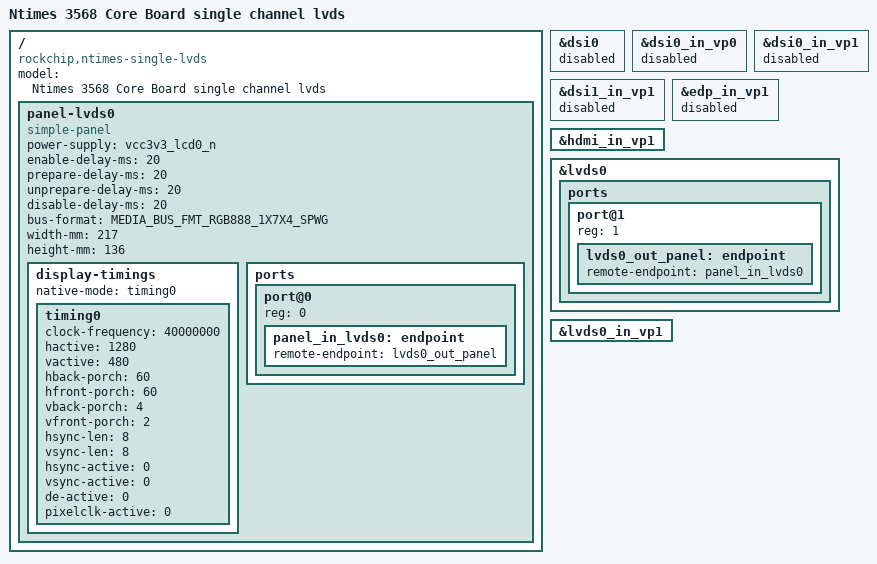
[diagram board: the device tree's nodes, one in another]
// SPDX-License-Identifier: (GPL-2.0+ OR MIT)
/*
 * Copyright (c) 2023 Rockchip Electronics Co., Ltd.
 */

#include <dt-bindings/display/media-bus-format.h>

/ {
	model = "Ntimes 3568 Core Board single channel lvds";
	compatible = "rockchip,ntimes-single-lvds", "rockchip,rk3568";

	/* panel: claa070wp03xg */
	panel-lvds0 {
		compatible = "simple-panel";
		//backlight = <&backlight>;
		power-supply = <&vcc3v3_lcd0_n>;
		enable-delay-ms = <20>;
		prepare-delay-ms = <20>;
		unprepare-delay-ms = <20>;
		disable-delay-ms = <20>;
		bus-format = <MEDIA_BUS_FMT_RGB888_1X7X4_SPWG>;
		width-mm = <217>;
		height-mm = <136>;

		display-timings {
			native-mode = <&timing0>;
			timing0: timing0 {
				clock-frequency = <40000000>;
				hactive = <1280>;
				vactive = <480>;
				hback-porch = <60>;
				hfront-porch = <60>;
				vback-porch = <4>;
				vfront-porch = <2>;
				hsync-len = <8>;
				vsync-len = <8>;
				hsync-active = <0>;
				vsync-active = <0>;
				de-active = <0>;
				pixelclk-active = <0>;
			};
		};

		ports {
			#address-cells = <1>;
			#size-cells = <0>;
			port@0 {
				reg = <0>;
				panel_in_lvds0: endpoint {
					remote-endpoint = <&lvds0_out_panel>;
				};
			};
		};
	};
};

&dsi0 {
	status = "disabled";
};

&dsi0_in_vp0 {
	status = "disabled";
};

&dsi0_in_vp1 {
	status = "disabled";
};

&dsi1_in_vp1 {
	status = "disabled";
};

&edp_in_vp1 {
	status = "disabled";
};

&hdmi_in_vp1 {
	status = "okay";
};

&lvds0 {
	status = "okay";
	ports {
		port@1 {
			reg = <1>;
			lvds0_out_panel: endpoint {
				remote-endpoint = <&panel_in_lvds0>;
			};
		};
	};
};

&lvds0_in_vp1 {
	status = "okay";
};
